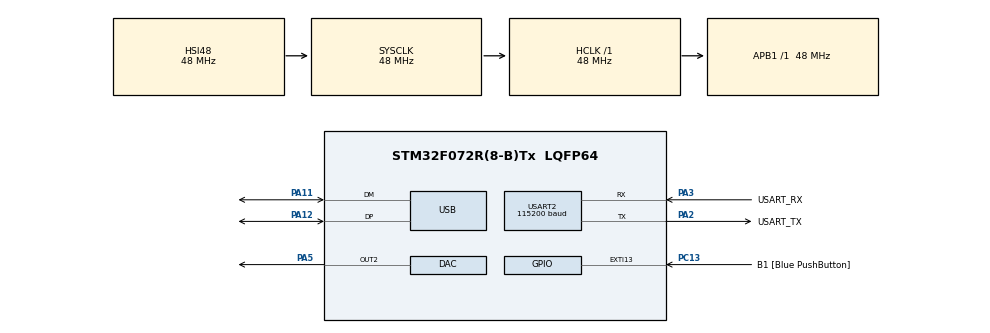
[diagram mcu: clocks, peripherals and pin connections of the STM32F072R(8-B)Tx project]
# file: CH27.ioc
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Mcu.Family=STM32F0
Mcu.Name=STM32F072R(8-B)Tx
Mcu.Package=LQFP64
NVIC.USB_IRQn=true\:0\:0\:false\:false\:true\:false\:true
PA11.Mode=Device
PA11.Signal=USB_DM
PA12.Mode=Device
PA12.Signal=USB_DP
PA13.GPIO_Label=TMS
PA13.Mode=Serial_Wire
PA13.Signal=SYS_SWDIO
PA14.GPIO_Label=TCK
PA14.Mode=Serial_Wire
PA14.Signal=SYS_SWCLK
PA2.GPIO_Label=USART_TX
PA2.GPIO_Mode=GPIO_MODE_AF_PP
PA2.GPIO_PuPd=GPIO_NOPULL
PA2.GPIO_Speed=GPIO_SPEED_FREQ_LOW
PA2.Mode=Asynchronous
PA2.Signal=USART2_TX
PA3.GPIO_Label=USART_RX
PA3.GPIO_Mode=GPIO_MODE_AF_PP
PA3.GPIO_PuPd=GPIO_NOPULL
PA3.GPIO_Speed=GPIO_SPEED_FREQ_LOW
PA3.Mode=Asynchronous
PA3.Signal=USART2_RX
PA5.Signal=COMP_DAC2_group
PC13.GPIO_Label=B1 [Blue PushButton]
PC13.GPIO_ModeDefaultEXTI=GPIO_MODE_IT_FALLING
PC13.Signal=GPXTI13
PC14-OSC32_IN.Mode=LSE-External-Oscillator
PC14-OSC32_IN.Signal=RCC_OSC32_IN
PC15-OSC32_OUT.Mode=LSE-External-Oscillator
PC15-OSC32_OUT.Signal=RCC_OSC32_OUT
PF0-OSC_IN.Mode=HSE-External-Clock-Source
PF0-OSC_IN.Signal=RCC_OSC_IN
PF1-OSC_OUT.Signal=RCC_OSC_OUT
ProjectManager.HeapSize=0x200
ProjectManager.StackSize=0x400
ProjectManager.TargetToolchain=STM32CubeIDE
RCC.AHBFreq_Value=48000000
RCC.APB1Freq_Value=48000000
RCC.APB1TimFreq_Value=48000000
RCC.FLatency-AdvancedSettings=FLASH_LATENCY_1
RCC.HCLKFreq_Value=48000000
RCC.PLLDivider=RCC_PREDIV_DIV2
RCC.PLLMUL=RCC_PLL_MUL12
RCC.PREFETCH_ENABLE-AdvancedSettings=1
RCC.SYSCLKFreq_VALUE=48000000
RCC.SYSCLKSource=RCC_SYSCLKSOURCE_HSI48
SH.COMP_DAC2_group.0=DAC_OUT2,DAC_OUT2
USART2.BaudRate=115200
USART2.VirtualMode=VM_ASYNC
USART2.VirtualMode-Asynchronous=VM_ASYNC
USB_DEVICE.CLASS_NAME_FS=CUSTOM_HID
USB_DEVICE.VirtualMode=CustomHid
USB_DEVICE.VirtualModeFS=Custom_Hid_FS
VP_USB_DEVICE_VS_USB_DEVICE_CUSTOM_HID_FS.Mode=CUSTOM_HID_FS
board=NUCLEO-F072RB

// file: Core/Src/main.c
/* USER CODE BEGIN Header */
/**
  ******************************************************************************
  * @file           : main.c
  * @brief          : Main program body
  ******************************************************************************
  * @attention
  *
  * <h2><center>&copy; Copyright (c) 2021 STMicroelectronics.
  * All rights reserved.</center></h2>
  *
  * This software component is licensed by ST under BSD 3-Clause license,
  * the "License"; You may not use this file except in compliance with the
  * License. You may obtain a copy of the License at:
  *                        opensource.org/licenses/BSD-3-Clause
  *
  ******************************************************************************
  */
/* USER CODE END Header */
#include "main.h"
#include "usb_device.h"

DAC_HandleTypeDef hdac;

UART_HandleTypeDef huart2;

void SystemClock_Config(void);
static void MX_GPIO_Init(void);
static void MX_USART2_UART_Init(void);
static void MX_DAC_Init(void);

int main(void)
{

  /* MCU Configuration--------------------------------------------------------*/

  /* Reset of all peripherals, Initializes the Flash interface and the Systick. */
  HAL_Init();

  /* Configure the system clock */
  SystemClock_Config();

  /* Initialize all configured peripherals */
  MX_GPIO_Init();
  MX_USART2_UART_Init();
  MX_DAC_Init();
  /* USER CODE BEGIN 2 */

  HAL_DAC_Start(&hdac, DAC_CHANNEL_2);
  MX_USB_DEVICE_Init();

  /* USER CODE END 2 */

  /* Infinite loop */
  while (1)
  {

  }
}

void SystemClock_Config(void)
{
  RCC_OscInitTypeDef RCC_OscInitStruct = {0};
  RCC_ClkInitTypeDef RCC_ClkInitStruct = {0};
  RCC_PeriphCLKInitTypeDef PeriphClkInit = {0};

  /** Initializes the RCC Oscillators according to the specified parameters
  * in the RCC_OscInitTypeDef structure.
  */
  RCC_OscInitStruct.OscillatorType = RCC_OSCILLATORTYPE_HSI48;
  RCC_OscInitStruct.HSI48State = RCC_HSI48_ON;
  RCC_OscInitStruct.PLL.PLLState = RCC_PLL_NONE;
  if (HAL_RCC_OscConfig(&RCC_OscInitStruct) != HAL_OK)
  {
    Error_Handler();
  }
  /** Initializes the CPU, AHB and APB buses clocks
  */
  RCC_ClkInitStruct.ClockType = RCC_CLOCKTYPE_HCLK|RCC_CLOCKTYPE_SYSCLK
                              |RCC_CLOCKTYPE_PCLK1;
  RCC_ClkInitStruct.SYSCLKSource = RCC_SYSCLKSOURCE_HSI48;
  RCC_ClkInitStruct.AHBCLKDivider = RCC_SYSCLK_DIV1;
  RCC_ClkInitStruct.APB1CLKDivider = RCC_HCLK_DIV1;

  if (HAL_RCC_ClockConfig(&RCC_ClkInitStruct, FLASH_LATENCY_1) != HAL_OK)
  {
    Error_Handler();
  }
  PeriphClkInit.PeriphClockSelection = RCC_PERIPHCLK_USB|RCC_PERIPHCLK_USART2;
  PeriphClkInit.Usart2ClockSelection = RCC_USART2CLKSOURCE_PCLK1;
  PeriphClkInit.UsbClockSelection = RCC_USBCLKSOURCE_HSI48;

  if (HAL_RCCEx_PeriphCLKConfig(&PeriphClkInit) != HAL_OK)
  {
    Error_Handler();
  }
}

static void MX_DAC_Init(void)
{

  DAC_ChannelConfTypeDef sConfig = {0};

  /** DAC Initialization
  */
  hdac.Instance = DAC;
  if (HAL_DAC_Init(&hdac) != HAL_OK)
  {
    Error_Handler();
  }
  /** DAC channel OUT2 config
  */
  sConfig.DAC_Trigger = DAC_TRIGGER_NONE;
  sConfig.DAC_OutputBuffer = DAC_OUTPUTBUFFER_ENABLE;
  if (HAL_DAC_ConfigChannel(&hdac, &sConfig, DAC_CHANNEL_2) != HAL_OK)
  {
    Error_Handler();
  }

}

static void MX_USART2_UART_Init(void)
{

  huart2.Instance = USART2;
  huart2.Init.BaudRate = 115200;
  huart2.Init.WordLength = UART_WORDLENGTH_8B;
  huart2.Init.StopBits = UART_STOPBITS_1;
  huart2.Init.Parity = UART_PARITY_NONE;
  huart2.Init.Mode = UART_MODE_TX_RX;
  huart2.Init.HwFlowCtl = UART_HWCONTROL_NONE;
  huart2.Init.OverSampling = UART_OVERSAMPLING_16;
  huart2.Init.OneBitSampling = UART_ONE_BIT_SAMPLE_DISABLE;
  huart2.AdvancedInit.AdvFeatureInit = UART_ADVFEATURE_NO_INIT;
  if (HAL_UART_Init(&huart2) != HAL_OK)
  {
    Error_Handler();
  }
  /* USER CODE BEGIN USART2_Init 2 */
  RetargetInit(&huart2);
  /* USER CODE END USART2_Init 2 */

}

static void MX_GPIO_Init(void)
{
  GPIO_InitTypeDef GPIO_InitStruct = {0};

  /* GPIO Ports Clock Enable */
  __HAL_RCC_GPIOC_CLK_ENABLE();
  __HAL_RCC_GPIOF_CLK_ENABLE();
  __HAL_RCC_GPIOA_CLK_ENABLE();

  /*Configure GPIO pin : B1_Pin */
  GPIO_InitStruct.Pin = B1_Pin;
  GPIO_InitStruct.Mode = GPIO_MODE_IT_RISING_FALLING;
  GPIO_InitStruct.Pull = GPIO_NOPULL;
  HAL_GPIO_Init(B1_GPIO_Port, &GPIO_InitStruct);

  HAL_NVIC_EnableIRQ(EXTI4_15_IRQn);
  HAL_NVIC_SetPriority(EXTI4_15_IRQn, 1, 0);
}

void Error_Handler(void)
{
  __disable_irq();
  while (1)
  {
  }
}
